AUTOSAR XML (schema 4-0-3)
# Copyright © Vector Informatik GmbH 2013
# License cannot be found!
# The created file must only be used with Vectors MICROSAR Basic Software. Please contact Vector Informatik to obtain a license.
standard types defined: boolean, sint8, uint16, uint8
package /VehicleProject
  system System
package /NM
  nm config NmConfig: can-nm-cluster-coupling=coupled-cluster=CAN00
    can nm cluster CAN00: communication-cluster=Comfort, nm-channel-id=0
      4 x can nm node:
        Console: controller=Console/CT_CAN00, nm-if-ecu=Console_CAN, tx-nm-pdu=NM_Console
        DOOR_le: controller=DOOR_le/CT_CAN00, nm-if-ecu=DOOR_le_CAN, rx-nm-pdu=[NM_Console, NM_DOORright, NM_Gateway], tx-nm-pdu=NM_DOORleft
        DOOR_ri: controller=DOOR_ri/CT_CAN00, nm-if-ecu=DOOR_ri_CAN, rx-nm-pdu=[NM_Console, NM_DOORleft, NM_Gateway], tx-nm-pdu=NM_DOORright
        Gateway: controller=Gateway/CT_CAN00, nm-if-ecu=Gateway_CAN, rx-nm-pdu=[NM_Console, NM_DOORleft, NM_DOORright], tx-nm-pdu=NM_Gateway
    nm-if-ecus:
      4 x nm ecu, all with nm-multiple-channels-enabled=false:
        Console_CAN: ecu-instance=Console
        DOOR_le_CAN: ecu-instance=DOOR_le
        DOOR_ri_CAN: ecu-instance=DOOR_ri
        Gateway_CAN: ecu-instance=Gateway
package /TP
  can tp config CAN00: communication-cluster=Comfort
    can tp channel TPCH: channel-id=0, channel-mode=FULL-DUPLEX-MODE
    tp-ecus:
      cycle-time-main-function=0.005, ecu-instance=Console
      cycle-time-main-function=0.005, ecu-instance=Dashboard
      cycle-time-main-function=0.005, ecu-instance=DOOR_le
      cycle-time-main-function=0.005, ecu-instance=DOOR_ri
      cycle-time-main-function=0.005, ecu-instance=Gateway
    5 x can tp node:
      TN_Console: connector=Console/CN_CAN00
      TN_Dashboard: connector=Dashboard/CN_CAN00
      TN_DOOR_le: connector=DOOR_le/CN_CAN00
      TN_DOOR_ri: connector=DOOR_ri/CN_CAN00
      TN_Gateway: connector=Gateway/CN_CAN00
package /Cluster
  can cluster Comfort: protocol-name=CAN  # CAN communication matrix for body electronics ******************************************************* implemented: turn lights, warning lights, windows
    can physical channel CHNL: comm-connectors=[Console/CN_CAN00, Dashboard/CN_CAN00, DOOR_le/CN_CAN00, DOOR_ri/CN_CAN00, Gateway/CN_CAN00]
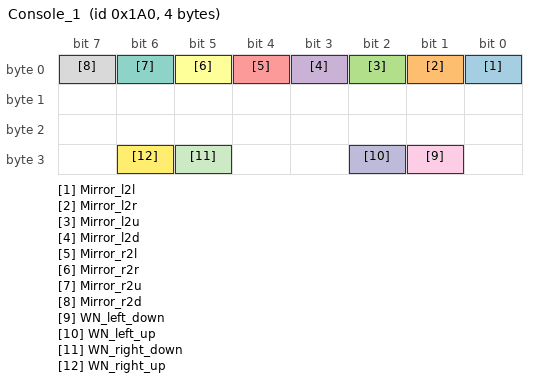
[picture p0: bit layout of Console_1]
      frame Console_1: id 0x1A0, from Console, to DOOR_le DOOR_ri, frame-length=4, can-addressing-mode=STANDARD
        pdu Console_1: length=4, minimum-delay=0.001, transmission-mode-false-timing=cyclic-timing={time-offset=0, time-period=0.02}, transmission-mode-true-timing=cyclic-timing={time-offset=0, time-period=0.02}, unused-bit-pattern=0
          signal Mirror_l2l: start 0, 1 bit, little-endian, init-value=0, base-type=boolean, transfer-property=PENDING
          signal Mirror_l2r: start 1, 1 bit, little-endian, init-value=0, base-type=boolean, transfer-property=PENDING
          signal Mirror_l2u: start 2, 1 bit, little-endian, init-value=0, base-type=boolean, transfer-property=PENDING
          signal Mirror_l2d: start 3, 1 bit, little-endian, init-value=0, base-type=boolean, transfer-property=PENDING
          signal Mirror_r2l: start 4, 1 bit, little-endian, init-value=0, base-type=boolean, transfer-property=PENDING
          signal Mirror_r2r: start 5, 1 bit, little-endian, init-value=0, base-type=boolean, transfer-property=PENDING
          signal Mirror_r2u: start 6, 1 bit, little-endian, init-value=0, base-type=boolean, transfer-property=PENDING
          signal Mirror_r2d: start 7, 1 bit, little-endian, init-value=0, base-type=boolean, transfer-property=PENDING
          signal WN_left_down: start 25, 1 bit, little-endian, init-value=0, base-type=boolean, transfer-property=PENDING, to DOOR_le
          signal WN_left_up: start 26, 1 bit, little-endian, init-value=0, base-type=boolean, transfer-property=PENDING, to DOOR_le
          signal WN_right_down: start 29, 1 bit, little-endian, init-value=0, base-type=boolean, transfer-property=PENDING, to DOOR_ri
          signal WN_right_up: start 30, 1 bit, little-endian, init-value=0, base-type=boolean, transfer-property=PENDING, to DOOR_ri
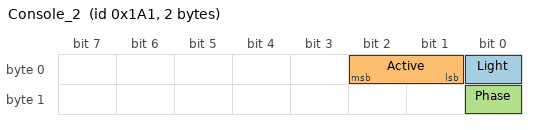
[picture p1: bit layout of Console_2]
      frame Console_2: id 0x1A1, from Console, frame-length=2, can-addressing-mode=STANDARD
        pdu Console_2: length=2, minimum-delay=0.001, transmission-mode-condition{data-filter={data-filter-type=MASKED-NEW-DIFFERS-X, mask=1, x=0}, i-signal-in-i-pdu=Light}, transmission-mode-false-timing={cyclic-timing={time-offset=0, time-period=0.5}, event-controlled-timing={number-of-repetitions=0, repetition-period=0}}, transmission-mode-true-timing=cyclic-timing={time-offset=0, time-period=0.1}, unused-bit-pattern=0
          signal Light: start 0, 1 bit, little-endian, init-value=0, base-type=boolean, transfer-property=PENDING
          signal Active: start 1, 2 bit, little-endian, data-type-policy=OVERRIDE, init-value=0, base-type=uint8, compu {0=None, 1=Turn_right, 2=Turn_left, 3=Warning}, transfer-property=PENDING
          signal Phase: start 8, 1 bit, little-endian, init-value=0, base-type=boolean, transfer-property=PENDING
      frame DebugMsg1: id 0x100, to Gateway, frame-length=8, can-addressing-mode=STANDARD
        pdu DebugMsg1: length=8, unused-bit-pattern=0
      frame Diag_Request: id 0x700, frame-length=8, can-addressing-mode=STANDARD
        n pdu Diag_Request_Tp: length=8
      frame Diag_Response: id 0x600, frame-length=8, can-addressing-mode=STANDARD
        n pdu Diag_Response_Tp: length=8
      frame DiagRequest: id 0x606, to DOOR_le, frame-length=8, can-addressing-mode=STANDARD
        n pdu DiagRequest_Tp: length=8
      frame DiagResponse_DoorLeft: id 0x607, from DOOR_le, frame-length=8, can-addressing-mode=STANDARD
        n pdu DiagResponse_DoorLeft_Tp: length=8
      frame DiagResponse_Motor: id 0x601, from Gateway, frame-length=8, can-addressing-mode=STANDARD
        n pdu DiagResponse_Motor_Tp: length=8
      frame DOOR_l: id 0x1F0, from DOOR_le, frame-length=1, can-addressing-mode=STANDARD
        pdu DOOR_l: length=1, minimum-delay=0.001, transmission-mode-false-timing=cyclic-timing={time-offset=0, time-period=0.03}, transmission-mode-true-timing=cyclic-timing={time-offset=0, time-period=0.03}, unused-bit-pattern=0
          signal WN_Position_l: start 0, 8 bit, little-endian, init-value=0, base-type=uint8, transfer-property=PENDING
      frame DOOR_r: id 0x1F1, from DOOR_ri, frame-length=1, can-addressing-mode=STANDARD
        pdu DOOR_r: length=1, minimum-delay=0.001, transmission-mode-false-timing=cyclic-timing={time-offset=0, time-period=0.03}, transmission-mode-true-timing=cyclic-timing={time-offset=0, time-period=0.03}, unused-bit-pattern=0
          signal WN_Position_r: start 0, 8 bit, little-endian, init-value=0, base-type=uint8, transfer-property=PENDING
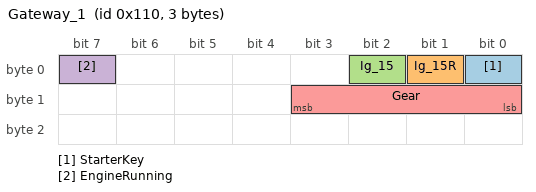
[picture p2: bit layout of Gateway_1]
      frame Gateway_1: id 0x110, from Gateway, to Console Dashboard, frame-length=3, can-addressing-mode=STANDARD
        pdu Gateway_1: length=3, minimum-delay=0.001, transmission-mode-false-timing=cyclic-timing={time-offset=0, time-period=0.1}, transmission-mode-true-timing=cyclic-timing={time-offset=0, time-period=0.1}, unused-bit-pattern=0
          signal StarterKey: start 0, 1 bit, little-endian, init-value=0, base-type=boolean, transfer-property=PENDING, to Dashboard
          signal Ig_15R: start 1, 1 bit, little-endian, init-value=0, base-type=boolean, transfer-property=PENDING, to Dashboard
          signal Ig_15: start 2, 1 bit, little-endian, init-value=0, base-type=boolean, transfer-property=PENDING, to Console Dashboard
          signal EngineRunning: start 7, 1 bit, little-endian, init-value=0, base-type=boolean, transfer-property=PENDING
          signal Gear: start 8, 4 bit, little-endian, init-value=0, base-type=sint8, transfer-property=PENDING, to Dashboard
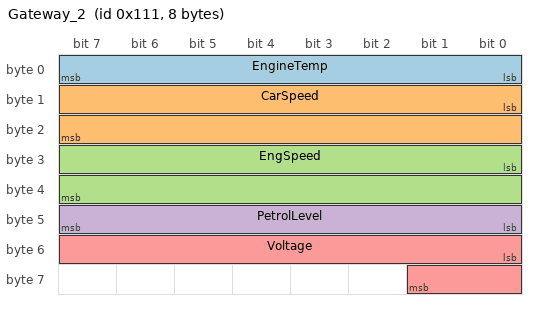
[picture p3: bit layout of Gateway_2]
      frame Gateway_2: id 0x111, from Gateway, to Dashboard, frame-length=8, can-addressing-mode=STANDARD
        pdu Gateway_2: length=8, minimum-delay=0.001, transmission-mode-false-timing=event-controlled-timing={number-of-repetitions=0, repetition-period=0}, transmission-mode-true-timing=event-controlled-timing={number-of-repetitions=0, repetition-period=0}, unused-bit-pattern=0
          transmission-mode-conditions:
            {data-filter={data-filter-type=MASKED-NEW-DIFFERS-MASKED-OLD, mask=255}, i-signal-in-i-pdu=EngineTemp}
            {data-filter={data-filter-type=MASKED-NEW-DIFFERS-MASKED-OLD, mask=65535}, i-signal-in-i-pdu=CarSpeed}
            {data-filter={data-filter-type=MASKED-NEW-DIFFERS-MASKED-OLD, mask=65535}, i-signal-in-i-pdu=EngSpeed}
            {data-filter={data-filter-type=MASKED-NEW-DIFFERS-MASKED-OLD, mask=255}, i-signal-in-i-pdu=PetrolLevel}
            {data-filter={data-filter-type=MASKED-NEW-DIFFERS-MASKED-OLD, mask=1023}, i-signal-in-i-pdu=Voltage}
          signal EngineTemp: start 0, 8 bit, little-endian, init-value=0, base-type=uint8, compu {; unit degC}, unit=degC, transfer-property=TRIGGERED-ON-CHANGE-WITHOUT-REPETITION, to Dashboard
          signal CarSpeed: start 8, 16 bit, little-endian, init-value=0, base-type=uint16, compu {phys=raw*0.5; unit mph}, unit=mph, transfer-property=TRIGGERED-ON-CHANGE-WITHOUT-REPETITION, to Dashboard
          signal EngSpeed: start 24, 16 bit, little-endian, init-value=0, base-type=uint16, compu {; unit rpm}, unit=rpm, transfer-property=TRIGGERED-ON-CHANGE-WITHOUT-REPETITION, to Dashboard
          signal PetrolLevel: start 40, 8 bit, little-endian, init-value=0, base-type=uint8, compu {; unit l}, unit=l, transfer-property=TRIGGERED-ON-CHANGE-WITHOUT-REPETITION, to Dashboard
          signal Voltage: start 48, 10 bit, little-endian, init-value=120, base-type=uint16, compu {phys=raw*0.1; unit V}, unit=V, transfer-property=TRIGGERED-ON-CHANGE-WITHOUT-REPETITION
      frame NM_Console: id 0x41A, from Console, to DOOR_le DOOR_ri Gateway, frame-length=4, can-addressing-mode=STANDARD
        nm pdu NM_Console: length=4, unused-bit-pattern=0
      frame NM_DOORleft: id 0x41B, from DOOR_le, to DOOR_ri Gateway, frame-length=4, can-addressing-mode=STANDARD
        nm pdu NM_DOORleft: length=4, unused-bit-pattern=0
      frame NM_DOORright: id 0x41C, from DOOR_ri, to DOOR_le Gateway, frame-length=4, can-addressing-mode=STANDARD
        nm pdu NM_DOORright: length=4, unused-bit-pattern=0
      frame NM_Gateway: id 0x41D, from Gateway, to DOOR_le DOOR_ri, frame-length=4, can-addressing-mode=STANDARD
        nm pdu NM_Gateway: length=4, unused-bit-pattern=0
      frame TP_Console: id 0x604, from Console, to Dashboard, frame-length=6, can-addressing-mode=STANDARD
        n pdu TP_Console: length=6
      frame TP_Dashboard: id 0x605, from Dashboard, to Console, frame-length=6, can-addressing-mode=STANDARD
        n pdu TP_Dashboard: length=6
      pdu triggering PT_Diag_Request: pdu=Diag_Request
      pdu triggering PT_Diag_Response: pdu=Diag_Response
      pdu triggering PT_DiagRequest: pdu=DiagRequest, to DOOR_le
      pdu triggering PT_DiagResponse_DoorLeft: pdu=DiagResponse_DoorLeft, from DOOR_le
      pdu triggering PT_DiagResponse_Motor: pdu=DiagResponse_Motor, from Gateway
      pdu triggering PT_TP_Dashboard: pdu=TP_Dashboard_TP, from Dashboard, to Console
package /ECU
  5 x ecu instance, all with com-configuration-rx-time-base=0.001, com-configuration-tx-time-base=0.001:
    Console: associated-com-i-pdu-group=[Console_oCAN00_Rx, Console_oCAN00_Tx]
      can communication controller CT_CAN00
      can communication connector CN_CAN00: comm-controller=Console/CT_CAN00
    Dashboard: associated-com-i-pdu-group=Dashboard_oCAN00_Rx
      can communication controller CT_CAN00
      can communication connector CN_CAN00: comm-controller=Dashboard/CT_CAN00
    DOOR_le: associated-com-i-pdu-group=[DOOR_le_oCAN00_Rx, DOOR_le_oCAN00_Tx]
      can communication controller CT_CAN00
      can communication connector CN_CAN00: comm-controller=DOOR_le/CT_CAN00
    DOOR_ri: associated-com-i-pdu-group=[DOOR_ri_oCAN00_Rx, DOOR_ri_oCAN00_Tx]
      can communication controller CT_CAN00
      can communication connector CN_CAN00: comm-controller=DOOR_ri/CT_CAN00
    Gateway: associated-com-i-pdu-group=Gateway_oCAN00_Tx
      can communication controller CT_CAN00
      can communication connector CN_CAN00: comm-controller=Gateway/CT_CAN00
package /IPDUGroup
  8 x i signal i pdu group:
    Console_oCAN00_Rx: communication-direction=IN, i-signal-i-pdus=Gateway_1
    Console_oCAN00_Tx: communication-direction=OUT, i-signal-i-pdus=[Console_1, Console_2]
    Dashboard_oCAN00_Rx: communication-direction=IN, i-signal-i-pdus=[Gateway_1, Gateway_2]
    DOOR_le_oCAN00_Rx: communication-direction=IN, i-signal-i-pdus=Console_1
    DOOR_le_oCAN00_Tx: communication-direction=OUT, i-signal-i-pdus=DOOR_l
    DOOR_ri_oCAN00_Rx: communication-direction=IN, i-signal-i-pdus=Console_1
    DOOR_ri_oCAN00_Tx: communication-direction=OUT, i-signal-i-pdus=DOOR_r
    Gateway_oCAN00_Tx: communication-direction=OUT, i-signal-i-pdus=[Gateway_1, Gateway_2]
package /PDU
  dcm i pdu Diag_Request: length=8, diag-pdu-type=DIAG-REQUEST
  dcm i pdu Diag_Response: length=8, diag-pdu-type=DIAG-RESPONSE
  dcm i pdu DiagRequest: length=8, diag-pdu-type=DIAG-REQUEST
  dcm i pdu DiagResponse_DoorLeft: length=8, diag-pdu-type=DIAG-RESPONSE
  dcm i pdu DiagResponse_Motor: length=8, diag-pdu-type=DIAG-RESPONSE
  dcm i pdu TP_Console: length=6, diag-pdu-type=DIAG-REQUEST
  dcm i pdu TP_Dashboard_TP: length=6, diag-pdu-type=DIAG-REQUEST
package /DataType/Unit
  5 x unit:
    U_degC: display-name=degC
    U_l: display-name=l
    U_mph: display-name=mph
    U_rpm: display-name=rpm
    U_V: display-name=V
